# STM32L063xx register map
File version: 1.0
Registers are 32-bit, read-write, reset 0x0 unless marked. A register's access mark holds for its fields unless they carry their own. Offsets are from the block's base; [hi:lo] are bit positions; {n}, {i} and the like mark numbered series.

## PWR — Power Control
Base 0x40007000
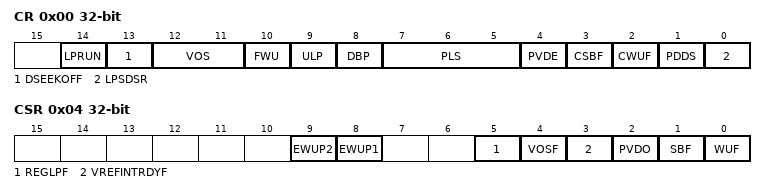
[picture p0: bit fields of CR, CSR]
0x00 CR — PWR power control register
  [14] LPRUN — Low power run mode
  [13] DSEEKOFF — Deep Sleep mode with EEPROM kept Off
  [12:11] VOS — VOS[1:0] bits (Voltage scaling range selection)
    1=SCALE1 (1.8V (range 1)); 2=SCALE2 (1.5V (range 2)); 3=SCALE3 (1.2V (range 3))
  [10] FWU — Fast wakeup
  [9] ULP — Ultra Low Power mode
  [8] DBP — Disable Backup Domain write protection
  [7:5] PLS — PLS[2:0] bits (PVD Level Selection)
    0=PVDLEVEL_0 (Voltage threshold detected by PVD 1.9 V); 1=PVDLEVEL_1 (Voltage threshold detected by PVD 2.1 V); 2=PVDLEVEL_2 (Voltage threshold detected by PVD 2.3 V); 3=PVDLEVEL_3 (Voltage threshold detected by PVD 2.5 V); 4=PVDLEVEL_4 (Voltage threshold detected by PVD 2.7 V); 5=PVDLEVEL_5 (Voltage threshold detected by PVD 2.9 V); 6=PVDLEVEL_6 (Voltage threshold detected by PVD 3.1 V); 7=PVDLEVEL_7 (External input analog voltage (Compare internally to VREFINT))
  [4] PVDE — Power Voltage Detector Enable
  [3] CSBF — Clear Standby Flag
  [2] CWUF — Clear Wakeup Flag
  [1] PDDS — Power Down Deepsleep
    0=STOP (Enter Stop mode when the CPU enters deepsleep); 1=STANDBY (Enter Standby mode when the CPU enters deepsleep)
  [0] LPSDSR — Low-power deepsleep/sleep/low power run
    0=MAIN (Voltage regulator in main mode during deepsleep/sleep/low-power run mode); 1=LOW_POWER (Voltage regulator in low-power mode during deepsleep/sleep/low-power run mode)
0x04 CSR — PWR power control/status register
  [9] EWUP2 — Enable WKUP pin 2
  [8] EWUP1 — Enable WKUP pin 1
  [5] REGLPF — Regulator LP flag
  [4] VOSF — Voltage Scaling select flag
  [3] VREFINTRDYF — Internal voltage reference (VREFINT) ready flag
  [2] PVDO — PVD Output
  [1] SBF — Standby Flag
  [0] WUF — Wakeup Flag

## DAC — Digital to Analog Converter
Base 0x40007400
Same registers: DAC1 0x40007400 (alternate view of DAC)
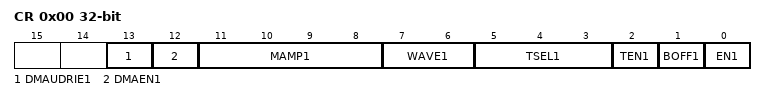
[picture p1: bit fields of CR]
0x00 CR — DAC control register
  [13] DMAUDRIE1 — DAC channel1 DMA Underrun interrupt enable
  [12] DMAEN1 — DAC channel1 DMA enable
  [11:8] MAMP1 — MAMP1[3:0] (DAC channel1 Mask/Amplitude selector)
  [7:6] WAVE1 — WAVE1[1:0] (DAC channel1 noise/triangle wave generation enable)
  [5:3] TSEL1 — TSEL1[2:0] (DAC channel1 Trigger selection)
  [2] TEN1 — DAC channel1 Trigger enable
  [1] BOFF1 — DAC channel1 output buffer disable
  [0] EN1 — DAC channel1 enable
0x04 SWTRIGR — DAC software trigger register
  [0] SWTRIG1 — DAC channel1 software trigger
0x08 DHR12R1 — DAC channel1 12-bit right-aligned data holding register
  [11:0] DACC1DHR — DAC channel1 12-bit Right aligned data
0x0C DHR12L1 — DAC channel1 12-bit left aligned data holding register
  [15:4] DACC1DHR — DAC channel1 12-bit Left aligned data
0x10 DHR8R1 — DAC channel1 8-bit right aligned data holding register
  [7:0] DACC1DHR — DAC channel1 8-bit Right aligned data
0x2C DOR1 — DAC channel1 data output register
  [11:0] DACC1DOR — DAC channel1 data output
0x34 SR — DAC status register
  [13] DMAUDR1 — DAC channel1 DMA underrun flag

## SYSCFG — SysTem Configuration
Base 0x40010000
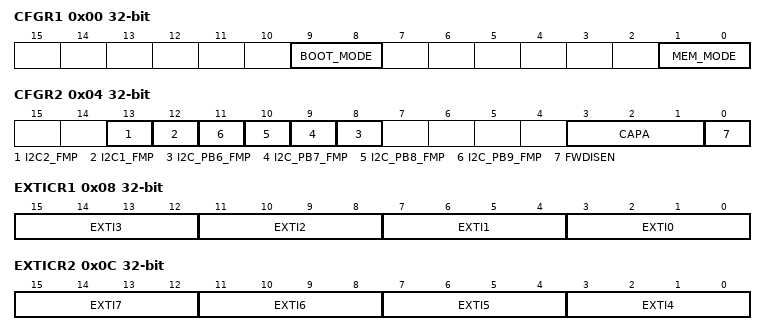
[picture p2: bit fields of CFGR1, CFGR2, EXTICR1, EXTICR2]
0x00 CFGR1 — SYSCFG configuration register 1
  [9:8] BOOT_MODE — SYSCFG_Boot mode Config
    0=FLASH (Main Flash memory boot mode); 1=SYSTEMFLASH (System Flash memory boot mode); 3=SRAM (SRAM boot mode)
  [1:0] MEM_MODE — SYSCFG_Memory Remap Config
    0=FLASH (Main Flash memory mapped at 0x00000000); 1=SYSTEMFLASH (System Flash memory mapped at 0x00000000); 3=SRAM (SRAM mapped at 0x00000000)
0x04 CFGR2 — SYSCFG configuration register 2
  [13] I2C2_FMP — I2C2 Fast mode plus
  [12] I2C1_FMP — I2C1 Fast mode plus
  [n+2] I2C_PB{n}_FMP (n=6..9) — I2C PB{n} Fast mode plus
  [3:1] CAPA — Connection of internal Vlcd rail to external capacitors
    2=VLCD1_PB12 (Connect PB12 pin to LCD_VLCD1 rails supply voltage); 1=VLCD2_PB2 (Connect PB2 pin to LCD_VLCD2 rails supply voltage); 4=VLCD3_PB0 (Connect PB0 pin to LCD_VLCD3 rails supply voltage)
  [0] FWDISEN — Firewall disable bit
0x08 EXTICR1 — SYSCFG external interrupt configuration register
  [4n+3:4n] EXTI{n} (n=0..3) — EXTI {n} configuration
0x0C EXTICR2 — SYSCFG external interrupt configuration register
  [4n-13:4n-16] EXTI{n} (n=4..7) — EXTI {n} configuration
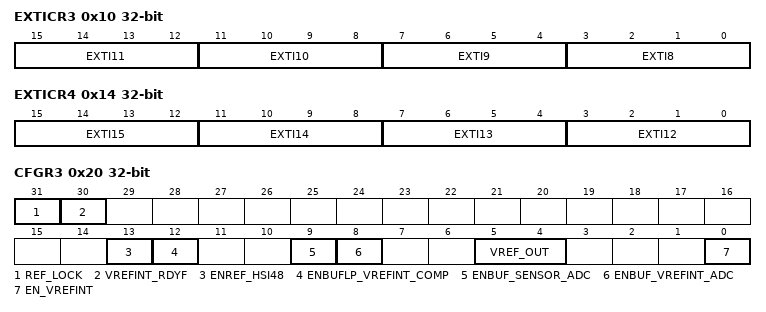
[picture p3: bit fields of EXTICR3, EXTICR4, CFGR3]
0x10 EXTICR3 — SYSCFG external interrupt configuration register
  [4n-29:4n-32] EXTI{n} (n=8..11) — EXTI {n} configuration
0x14 EXTICR4 — SYSCFG external interrupt configuration register
  [4n-45:4n-48] EXTI{n} (n=12..15) — EXTI {n} configuration
0x20 CFGR3 — SYSCFG configuration register 3
  [31] REF_LOCK — CFGR3 lock bit
  [30] VREFINT_RDYF — VREFINT ready flag
  [13] ENREF_HSI48 — VREFINT reference or 48 MHz RC oscillator enable bit
  [12] ENBUFLP_VREFINT_COMP — VREFINT reference for comparator 2 enable bit
  [9] ENBUF_SENSOR_ADC — Sensor reference for ADC enable bit
  [8] ENBUF_VREFINT_ADC — VREFINT reference for ADC enable bit
  [5:4] VREF_OUT — Verf_ADC connection bit
    0=NONE (No pad connected to VREFINT_ADC); 1=IO1 (PB0 connected to VREFINT_ADC); 2=IO2 (PB1 connected to VREFINT_ADC); 3=IO1_IO2 (PB0 and PB1 connected to VREFINT_ADC)
  [0] EN_VREFINT — Vref Enable bit
